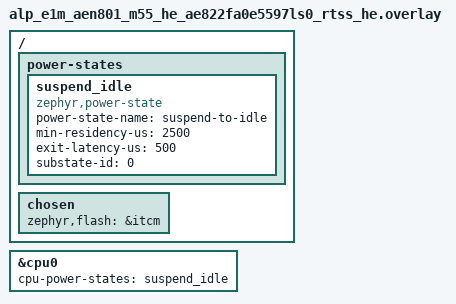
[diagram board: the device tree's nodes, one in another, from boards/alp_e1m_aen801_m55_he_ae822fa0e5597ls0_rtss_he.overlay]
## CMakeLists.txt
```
# SPDX-License-Identifier: Apache-2.0
#
# Stage-B PM deep-sleep (suspend-to-idle / IWIC) for the E1M-AEN801 (Alif
# Ensemble E8, Cortex-M55-HE).
#
# Brings a minimal Alif PM up over the pinned Zephyr 4.4.0 tree -- which ships no
# Alif pm_state_set and does not select HAS_PM -- and proves CONFIG_PM
# suspend-to-idle (deep IWIC sleep): the kernel idle path selects
# PM_STATE_SUSPEND_TO_IDLE, pm_state_set() (src/alif_pm_iwic.c) programs the AON
# WICCONTROL register (0x1A604010, bit8 WIC / bit9 IWIC) and parks the core in
# WFI; SysTick wakes it.  A wake beacon/heartbeat in global SRAM0 (0x02000000)
# advances each round.
#
# The HAS_PM select lives in this app's Kconfig; the suspend_idle power-state +
# cpu-power-states live in the board overlay.  No edit to upstream zephyr/.
#
# Standalone Zephyr app (no alp_project.py board.yaml flow): build with
#   ZEPHYR_BASE=<zephyr-base> west build \
#     -b alp_e1m_aen801_m55_he/ae822fa0e5597ls0/rtss_he <this-dir> -- \
#     "-DEXTRA_ZEPHYR_MODULES=<alp-sdk>;<hal_alif>"

cmake_minimum_required(VERSION 3.20)

# No DTC_OVERLAY_FILE: Zephyr applies boards/<fully-qualified-board>.overlay
# by itself, so the AEN801 and AEN803 targets each read their own file.

find_package(Zephyr REQUIRED HINTS $ENV{ZEPHYR_BASE})
project(aen_power_iwic LANGUAGES C)

target_sources(app PRIVATE
	src/main.c
	src/alif_pm_iwic.c
)
```

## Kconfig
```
# Copyright (c) 2026 Alp Lab AB
# SPDX-License-Identifier: Apache-2.0
#
# Stage-B PM bring-up over the pinned Zephyr 4.4.0 tree.
#
# `config PM` (subsys/pm/Kconfig) `depends on SYS_CLOCK_EXISTS && HAS_PM`, and
# `config HAS_PM` is a prompt-less bool that can ONLY be `select`ed by a SoC/board
# (it has no menuconfig prompt, so it cannot be set from prj.conf).  Pinned
# upstream Zephyr's Alif Ensemble SoC layer does NOT select it (only the
# alifsemi/zephyr_alif fork does).  This app-level Kconfig selects it so the
# CONFIG_PM=y in prj.conf becomes reachable -- the Tier-1.5 plumbing that, with
# src/alif_pm_iwic.c (pm_state_set) and the board overlay (suspend_idle
# power-state), brings a minimal Alif PM up with no edit to upstream zephyr/.
#
# Gated on the M55-HE SoC core (SOC_AE822FA0E5597LS0_RTSS_HE, true on any SKU
# built for that core): HAS_PM is only honoured (and pm_state_set is only
# correct) on the M55 core where this app's WICCONTROL(HE)=0x1A604010 hook
# applies -- a SoC-core fact, not a board/SKU one.

if SOC_AE822FA0E5597LS0_RTSS_HE

config HAS_PM
	default y

endif # SOC_AE822FA0E5597LS0_RTSS_HE

source "Kconfig.zephyr"
```

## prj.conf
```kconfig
# SPDX-License-Identifier: Apache-2.0
#
# Stage-B PM deep-sleep (suspend-to-idle / IWIC) for the E1M-AEN801 (Alif
# Ensemble E8, M55-HE), bench RAM-run via J-Link.  Unlike the peripheral
# examples (which now default to the Alp UART console), the PM apps deliberately
# keep the RAM console: console output must survive the deep-sleep/WFI path
# (a UART mid-suspend can gate its clock and drop bytes), so it is retargeted to
# a RAM buffer the human reads over SWD (mem8 of 'ram_console_buf') and decodes.

# --- RAM console (read 'ram_console_buf' over SWD) ---------------------------
CONFIG_RAM_CONSOLE=y
CONFIG_RAM_CONSOLE_BUFFER_SIZE=4096
CONFIG_UART_CONSOLE=n
CONFIG_CONSOLE=y
CONFIG_SERIAL=n
CONFIG_PRINTK=y

# --- Stage-B: bring up CONFIG_PM over the pinned tree ------------------------
# Pinned upstream Zephyr 4.4.0's Alif E8 SoC does NOT `select HAS_PM` and ships
# no pm_state_set (only the alifsemi/zephyr_alif fork's soc/alif/common/rtss/
# power.c does), so `config PM` (subsys/pm/Kconfig: depends on SYS_CLOCK_EXISTS
# && HAS_PM) was unreachable AND unlinkable.  This app closes BOTH halves at the
# app level with NO edit to upstream zephyr/:
#   - Kconfig (this app) `select HAS_PM`  -> makes `config PM` reachable;
#   - src/alif_pm_iwic.c defines pm_state_set()/pm_state_exit_post_ops() -> PM links;
#   - the board overlay enables the suspend_idle power-state + cpu-power-states.
CONFIG_PM=y

# Device PM is not needed for the CPU-only suspend-to-idle path and would pull in
# per-device suspend/resume the bench peripherals don't implement; keep it off.
CONFIG_PM_DEVICE=n

# SysTick is the M55 system clock (CONFIG_CORTEX_M_SYSTICK default y) and the
# wake source for the deep IWIC sleep.  SysTick is architectural exception #15,
# NOT an NVIC IRQ, so it is unaffected by the IWIC "interrupts 0-63 only" wake
# range -- it always wakes the WFI inside pm_state_set().  Tickless lets the
# kernel program SysTick to the next timeout before the PM idle, so the policy
# sees a real idle window and selects suspend-to-idle, and the wake k_timer
# still fires.
CONFIG_TICKLESS_KERNEL=y

# E8 D-cache maintenance loop hangs on this silicon (shared bench rule); and
# the SRAM0 liveness beacon (see src/main.c) must be coherent with the host
# read over the system bus, so keep the D-cache off (a cached beacon write
# could sit in the core's D-cache, unseen by the AXI-AP read).
CONFIG_DCACHE=n

# Keep the image small + deterministic for a RAM-run.  LOG MUST stay off --
# CONFIG_LOG=y reroutes printk into the logging subsystem, which has no
# RAM-console backend, so the RESULT line never reaches 'ram_console_buf'.
CONFIG_LOG=n
```

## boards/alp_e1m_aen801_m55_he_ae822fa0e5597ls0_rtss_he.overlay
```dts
/*
 * Copyright (c) 2026 Alp Lab AB
 * SPDX-License-Identifier: Apache-2.0
 *
 * Stage-B PM deep-sleep overlay for the E1M-AEN801 (Alif Ensemble E8, M55-HE),
 * bench RAM-run via J-Link.
 *
 * Two jobs:
 *
 *  1. The Tier-1.5 PM devicetree the pinned Zephyr 4.4.0 Alif HE dtsi omits.
 *     Pinned dts/arm/alif/ensemble/common/ensemble_rtss_he.dtsi has the cpu0
 *     node but NO `power-states` table and NO `cpu-power-states` (only the
 *     alifsemi/zephyr_alif fork's dtsi:153-197 has them).  We add the
 *     `suspend_idle` zephyr,power-state (transcribed from the fork dtsi:154-162:
 *     power-state-name "suspend-to-idle", min-residency-us 2500, exit-latency-us
 *     500, substate-id 0) and point cpu0 cpu-power-states at it, so the PM
 *     policy can select PM_STATE_SUSPEND_TO_IDLE and call the IWIC pm_state_set
 *     hook (src/alif_pm_iwic.c).  Only suspend_idle is enabled -- the deeper
 *     fork states (standby_s2ram / stop_s2ram / subsys_off) need the S2RAM
 *     context-save + Secure-Enclave path that is the full-fork-port follow-up,
 *     so they are deliberately not declared here.
 *
 *  2. The standard bench RAM-run retarget (run from ITCM, drop the MCUboot
 *     code-partition fixup), matching the sibling aen-* apps -- the smoke uses
 *     only architectural SysTick + a global-SRAM0 beacon (0x02000000), no
 *     peripheral nodes.
 */

/ {
	power-states {
		suspend_idle: suspend_idle {
			compatible = "zephyr,power-state";
			power-state-name = "suspend-to-idle";
			min-residency-us = <2500>;
			exit-latency-us = <500>;
			substate-id = <0>;
			status = "okay";
		};
	};

	chosen {
		/* PATH-REFERENCE form (&itcm), NOT the <&itcm> phandle-array form:
		 * the phandle-array form yields CONFIG_FLASH_SIZE=0 and the image
		 * overflows the (empty) FLASH region at link time. */
		zephyr,flash = &itcm;
		/delete-property/ zephyr,code-partition;
	};
};

/* Wire the M55-HE core to the suspend-to-idle power-state (the pinned cpu0 node
 * carries no cpu-power-states). */
&cpu0 {
	cpu-power-states = <&suspend_idle>;
};
```

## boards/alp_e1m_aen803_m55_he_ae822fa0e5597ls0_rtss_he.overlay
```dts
/*
 * Copyright (c) 2026 Alp Lab AB
 * SPDX-License-Identifier: Apache-2.0
 *
 * Stage-B PM deep-sleep overlay for the E1M-AEN803 (Alif Ensemble E8, M55-HE),
 * bench RAM-run via J-Link.
 *
 * Two jobs:
 *
 *  1. The Tier-1.5 PM devicetree the pinned Zephyr 4.4.0 Alif HE dtsi omits.
 *     Pinned dts/arm/alif/ensemble/common/ensemble_rtss_he.dtsi has the cpu0
 *     node but NO `power-states` table and NO `cpu-power-states` (only the
 *     alifsemi/zephyr_alif fork's dtsi:153-197 has them).  We add the
 *     `suspend_idle` zephyr,power-state (transcribed from the fork dtsi:154-162:
 *     power-state-name "suspend-to-idle", min-residency-us 2500, exit-latency-us
 *     500, substate-id 0) and point cpu0 cpu-power-states at it, so the PM
 *     policy can select PM_STATE_SUSPEND_TO_IDLE and call the IWIC pm_state_set
 *     hook (src/alif_pm_iwic.c).  Only suspend_idle is enabled -- the deeper
 *     fork states (standby_s2ram / stop_s2ram / subsys_off) need the S2RAM
 *     context-save + Secure-Enclave path that is the full-fork-port follow-up,
 *     so they are deliberately not declared here.
 *
 *  2. The standard bench RAM-run retarget (run from ITCM, drop the MCUboot
 *     code-partition fixup), matching the sibling aen-* apps -- the smoke uses
 *     only architectural SysTick + a global-SRAM0 beacon (0x02000000), no
 *     peripheral nodes.
 */

/ {
	power-states {
		suspend_idle: suspend_idle {
			compatible = "zephyr,power-state";
			power-state-name = "suspend-to-idle";
			min-residency-us = <2500>;
			exit-latency-us = <500>;
			substate-id = <0>;
			status = "okay";
		};
	};

	chosen {
		/* PATH-REFERENCE form (&itcm), NOT the <&itcm> phandle-array form:
		 * the phandle-array form yields CONFIG_FLASH_SIZE=0 and the image
		 * overflows the (empty) FLASH region at link time. */
		zephyr,flash = &itcm;
		/delete-property/ zephyr,code-partition;
	};
};

/* Wire the M55-HE core to the suspend-to-idle power-state (the pinned cpu0 node
 * carries no cpu-power-states). */
&cpu0 {
	cpu-power-states = <&suspend_idle>;
};
```

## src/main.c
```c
/*
 * Copyright (c) 2026 Alp Lab AB
 * SPDX-License-Identifier: Apache-2.0
 *
 * Stage-B low-power IWIC deep-sleep example for the E1M-AEN801 (Alif Ensemble
 * E8, Cortex-M55-HE).  Where Stage-A (aen-power-smoke) proved a plain
 * architectural WFI via the kernel idle path with NO PM subsystem, Stage-B
 * brings the Alif PM layer up over the pinned Zephyr 4.4.0 tree and proves the
 * CONFIG_PM suspend-to-idle (deep IWIC sleep) path:
 *
 *   1. boot, RAM console up;
 *   2. report the PM wiring as a bind-regcheck (CONFIG_PM built in, HAS_PM
 *      selected, the suspend_idle power-state node present + enabled, the
 *      pm_state_set IWIC hook linked);
 *   3. let the kernel idle into the PM policy: main blocks on a periodic
 *      k_timer's semaphore long enough that the PM policy selects
 *      PM_STATE_SUSPEND_TO_IDLE, so pm_state_set() programs WICCONTROL (deep
 *      IWIC sleep) and the core parks in WFI until SysTick wakes it;
 *   4. a wake "beacon" in global SRAM0 (0x02000000, master-agnostic addr)
 *      advances every round and k_uptime_get() moves forward -- i.e. we entered
 *      the PM deep-sleep state and came back, repeatedly;
 *   5. RESULT PASS / FAIL on one line.
 *
 * The beacon layout matches the Stage-A smoke (read mem32 of 0x02000000 over the
 * system AXI-AP as an AP-agnostic witness next to the console RESULT line):
 *   SRAM0[0] = 0xA11FE000  magic ("ALIVE")
 *   SRAM0[1] = SCB.CPUID         (0x411FD220 = Cortex-M55)
 *   SRAM0[2] = completed PM sleep/wake rounds (advances => core woke)
 *   SRAM0[3] = final RESULT code (1 = PASS, 2 = FAIL; 0 = not finished)
 *
 * WHY THIS IS THE STAGE-B MILESTONE
 * ---------------------------------
 * Pinned upstream Zephyr 4.4.0's Alif E8 SoC neither selects HAS_PM nor ships a
 * pm_state_set(), so CONFIG_PM was previously unreachable AND unlinkable (see
 * aen-power-smoke).  This example carries the Tier-1.5 plumbing that closes the
 * gap at the app/board level, with no edit to upstream zephyr/:
 *   - prj.conf turns CONFIG_PM on;
 *   - Kconfig (this app) `select HAS_PM` so `config PM` becomes reachable;
 *   - the board overlay enables the `suspend_idle` zephyr,power-state node and
 *     wires cpu0 cpu-power-states to it;
 *   - src/alif_pm_iwic.c supplies pm_state_set()/pm_state_exit_post_ops()
 *     driving the AON WICCONTROL register (0x1A604010, bit8 WIC / bit9 IWIC).
 *
 * suspend-to-idle (deep IWIC sleep) is the lightest Alif deep sleep: it needs no
 * S2RAM context save and no Secure-Enclave retention call, so it builds + runs
 * standalone.  suspend-to-ram / soft-off remain the full-fork-port follow-up.
 *
 * Console is the RAM buffer 'ram_console_buf' (see prj.conf); the bench app UART
 * is not USB-wired.  BENCH-VALIDATION app -- not a customer teaching example.
 */

#include <zephyr/kernel.h>
#include <zephyr/devicetree.h>
#include <zephyr/sys/printk.h>

/* Cortex-M System Control Block CPUID, by absolute address (no CMSIS header). */
/* Deep-sleep entries counted by src/alif_pm_iwic.c. */
extern volatile uint32_t aen_iwic_entries;

#define SCB_CPUID (*(volatile uint32_t *)0xE000ED00U)

/* Global SRAM0 liveness beacon (always-on on-chip SRAM, master-agnostic addr). */
#define SRAM0_BEACON ((volatile uint32_t *)0x02000000U)
#define BEACON_MAGIC 0xA11FE000U /* "ALIVE" */

#define RESULT_NONE 0U
#define RESULT_PASS 1U
#define RESULT_FAIL 2U

/* Number of PM sleep/wake rounds, and the wake-timer period.  The period is
 * comfortably above the suspend_idle min-residency-us (2500 us) so the PM policy
 * actually selects suspend-to-idle each idle window. */
#define PM_ROUNDS    8U
#define WAKE_TICK_MS 50U

/*
 * Compile-time PM-wiring facts -- the Stage-B bind-regcheck.  Each is a pure
 * Kconfig/DT predicate proving the PM plumbing is in place at build time; the
 * runtime rounds below then prove the state is actually entered + exited.
 */
#if defined(CONFIG_PM)
#define PM_BUILT 1
#else
#define PM_BUILT 0
#endif

#define SUSPEND_IDLE_NODE DT_NODELABEL(suspend_idle)
#define SUSPEND_IDLE_OK   DT_NODE_HAS_STATUS(SUSPEND_IDLE_NODE, okay)

static K_SEM_DEFINE(wake_sem, 0, 1);

static void wake_timer_fn(struct k_timer *t)
{
	ARG_UNUSED(t);
	k_sem_give(&wake_sem);
}

static K_TIMER_DEFINE(wake_timer, wake_timer_fn, NULL);

int main(void)
{
	uint32_t cpuid = SCB_CPUID;
	int64_t  t_start, t_now, t_prev;
	uint32_t advanced = 0U;

	SRAM0_BEACON[0] = BEACON_MAGIC;
	SRAM0_BEACON[1] = cpuid;
	SRAM0_BEACON[2] = 0U;
	SRAM0_BEACON[3] = RESULT_NONE;

	printk("\n=== AEN801 Stage-B PM deep-sleep (suspend-to-idle / IWIC) ===\n");

	/* Step 1: report the PM wiring (bind-regcheck of the Tier-1.5 plumbing). */
	printk("PM wiring: CONFIG_PM=%d suspend_idle-node=%d "
	       "WICCONTROL(HE)=0x1A604010 (bit8 WIC / bit9 IWIC)\n",
	       PM_BUILT,
	       (int)SUSPEND_IDLE_OK);

	if (!PM_BUILT || !SUSPEND_IDLE_OK) {
		SRAM0_BEACON[3] = RESULT_FAIL;
		printk("RESULT FAIL: PM not wired (CONFIG_PM=%d suspend_idle=%d) -- "
		       "Stage-B plumbing missing\n",
		       PM_BUILT,
		       (int)SUSPEND_IDLE_OK);
		return 0;
	}

	t_start = k_uptime_get();
	t_prev  = t_start;
	printk("boot uptime=%lld ms; CPUID=0x%08x; taking %u PM suspend-to-idle "
	       "rounds (~%u ms each)\n",
	       t_start,
	       cpuid,
	       PM_ROUNDS,
	       WAKE_TICK_MS);

	k_timer_start(&wake_timer, K_MSEC(WAKE_TICK_MS), K_MSEC(WAKE_TICK_MS));

	for (uint32_t i = 0U; i < PM_ROUNDS; i++) {
		/*
		 * Block on the timer semaphore: main de-schedules, the kernel
		 * idle thread runs the PM policy, which -- with the idle window
		 * (~WAKE_TICK_MS) above suspend_idle's min-residency-us --
		 * selects PM_STATE_SUSPEND_TO_IDLE.  pm_state_set() then programs
		 * WICCONTROL for deep IWIC sleep and parks the core in WFI; the
		 * SysTick-backed k_timer expiry wakes it and releases us.
		 */
		k_sem_take(&wake_sem, K_FOREVER);

		t_now = k_uptime_get();
		if (t_now > t_prev) {
			advanced++;
		}
		t_prev = t_now;

		SRAM0_BEACON[2] = i + 1U;

		printk("round %u/%u: woke from PM idle, beacon=%u uptime=%lld ms\n",
		       i + 1U,
		       PM_ROUNDS,
		       (uint32_t)SRAM0_BEACON[2],
		       t_now);
	}

	k_timer_stop(&wake_timer);
	t_now = k_uptime_get();

	if (SRAM0_BEACON[2] != PM_ROUNDS) {
		SRAM0_BEACON[3] = RESULT_FAIL;
		printk("RESULT FAIL: beacon=%u expected %u (a PM round did not "
		       "complete)\n",
		       (uint32_t)SRAM0_BEACON[2],
		       PM_ROUNDS);
		return 0;
	}
	if (aen_iwic_entries < PM_ROUNDS) {
		SRAM0_BEACON[3] = RESULT_FAIL;
		printk("RESULT FAIL: the IWIC hook ran %u times for %u rounds (the core "
		       "woke from plain idle, not from the PM deep-sleep state)\n",
		       (uint32_t)aen_iwic_entries,
		       PM_ROUNDS);
		return 0;
	}
	if (advanced != PM_ROUNDS) {
		SRAM0_BEACON[3] = RESULT_FAIL;
		printk("RESULT FAIL: uptime advanced on only %u/%u rounds "
		       "(core not waking from PM idle?)\n",
		       advanced,
		       PM_ROUNDS);
		return 0;
	}

	SRAM0_BEACON[3] = RESULT_PASS;
	printk("RESULT PASS: %u PM suspend-to-idle (deep IWIC) rounds entered + "
	       "woken; uptime %lld->%lld ms (beacon=%u, IWIC entries=%u)\n",
	       PM_ROUNDS,
	       t_start,
	       t_now,
	       (uint32_t)SRAM0_BEACON[2],
	       (uint32_t)aen_iwic_entries);
	return 0;
}
```

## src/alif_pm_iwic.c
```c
/*
 * Copyright (c) 2026 Alp Lab AB
 * SPDX-License-Identifier: Apache-2.0
 *
 * Stage-B Alif IWIC deep-sleep PM hook for the E1M-AEN801 (Ensemble E8,
 * Cortex-M55-HE) -- a minimal CONFIG_PM pm_state_set() that the pinned upstream
 * Zephyr 4.4.0 Alif SoC layer does NOT provide.
 *
 * WHY THIS FILE EXISTS (the pinned-tree PM gap)
 * ---------------------------------------------
 * Upstream Zephyr's PM subsystem calls pm_state_set() unconditionally
 * (subsys/pm/pm.c:246) and each SoC is expected to supply it (every other SoC
 * ships soc/<vendor>/.../power.c with a __weak pm_state_set).  The pinned
 * Zephyr 4.4.0 Alif Ensemble SoC layer ships NO power.c and does NOT
 * `select HAS_PM` (only the alifsemi/zephyr_alif FORK's
 * soc/alif/common/rtss/power.c does).  So over the pinned tree CONFIG_PM is
 * both unreachable (HAS_PM unselected) AND unlinkable (no pm_state_set).
 *
 * This Tier-1.5 file closes BOTH halves at the app/board level, with no edit to
 * upstream zephyr/:  the companion Kconfig `select HAS_PM`s, and this TU defines
 * pm_state_set()/pm_state_exit_post_ops() so CONFIG_PM links.  It is the in-tree
 * "thin over the vendor SDK" body the SoC layer omits; it deliberately
 * implements ONLY the suspend-to-idle (deep IWIC) state -- the lightest Alif
 * deep sleep, which needs no S2RAM context save and no Secure-Enclave call, so
 * it is buildable + bench-runnable standalone.  suspend-to-ram / soft-off
 * (EWIC + subsystem-off + SE retention config) are intentionally left to the
 * full fork power.c port; entering them here would be a no-op/!-EBUSY at best.
 *
 * REGISTER FACTS (all confirmed against the Alif CMSIS DFP, E8 = AE822FA0E5597)
 * ---------------------------------------------------------------------------
 *   AON base            = 0x1A604000   (DFP soc.h: AON_BASE)
 *   AON.RTSS_HE_CTRL    = AON + 0x10   (DFP soc.h AON_Type: RTSS_HE_CTRL @0x10)
 *   WICCONTROL (HE)     = 0x1A604010   (== AON.RTSS_HE_CTRL; this is the HE core
 *                                       WIC-control register)
 *   WICCONTROL bit 8    = WIC enable   (DFP pm.c WICCONTROL_WIC_Pos = 8)
 *   WICCONTROL bit 9    = IWIC select  (DFP pm.c WICCONTROL_IWIC_Pos = 9;
 *                                       1 = IWIC, 0 = EWIC)
 * The deep-sleep entry sequence (set WICCONTROL WIC|IWIC, raise CPDLPSTATE.CLPSTATE
 * to ON_CLK_OFF to avoid core state loss, set SCB SLEEPDEEP, DSB/ISB, WFI, then
 * restore) mirrors the Alif DFP pm.c pm_core_enter_deep_sleep() and the
 * Apache-2.0 fork soc/alif/common/rtss/power.c.  IWIC wake sources are NVIC
 * interrupts 0-63 + events/NMI/debug (DFP pm.c note); the M55 SysTick is
 * architectural exception #15, NOT an NVIC IRQ, and always wakes WFI/WFE.
 *
 * Console / bench: this file carries no I/O; the example main() reports the
 * RESULT line over the RAM console.  No /home paths, no DFP source, no
 * license-gated content -- only the transcribed register addresses/bits above.
 */

#include <zephyr/kernel.h>
#include <zephyr/pm/pm.h>
#include <zephyr/sys/sys_io.h>

/*
 * WICCONTROL for the RTSS-HE core, by absolute address (the pinned Alif SoC
 * header exposes no AON struct / macro -- soc.h is bare CMSIS).  HE core only:
 * the HP core would use AON.RTSS_HP_CTRL = AON_BASE + 0x0 = 0x1A604000.
 */
#define AEN_AON_BASE      0x1A604000UL
#define AEN_WICCONTROL_HE (AEN_AON_BASE + 0x10UL) /* AON.RTSS_HE_CTRL */

#define WICCONTROL_WIC_Pos  8U
#define WICCONTROL_WIC_Msk  (1UL << WICCONTROL_WIC_Pos)
#define WICCONTROL_IWIC_Pos 9U
#define WICCONTROL_IWIC_Msk (1UL << WICCONTROL_IWIC_Pos)

/* WICCONTROL bit9 select values. */
#define PM_WIC_IS_EWIC 0U /* WIC used is EWIC */
#define PM_WIC_IS_IWIC 1U /* WIC used is IWIC */

/*
 * CPDLPSTATE.CLPSTATE low-power-state field values (M55 core power domain).
 * We raise to ON_CLK_OFF before an IWIC sleep so the core does NOT lose state
 * (the IWIC + CPU share a power domain, so both must stay on to wake).
 */
#define PM_LPSTATE_ON         0U
#define PM_LPSTATE_ON_CLK_OFF 1U

/*
 * Architectural deep WIC sleep: program WICCONTROL, set SLEEPDEEP, barrier, WFI.
 * Called with interrupts disabled.  Returns after the wake interrupt fires.
 */
/* Deep-sleep entries actually taken by the PM hook. main.c requires one per
 * round: a wake alone would also follow a plain kernel-idle WFI, so it proves
 * nothing about the PM policy having selected this state. */
volatile uint32_t aen_iwic_entries;

static void aen_enter_wic_sleep(uint32_t wic_is_iwic)
{
	uint32_t regval = WICCONTROL_WIC_Msk | (wic_is_iwic ? WICCONTROL_IWIC_Msk : 0U);

	aen_iwic_entries++;

	/* Select deep WIC sleep of the requested type (IWIC here). */
	sys_write32(regval, AEN_WICCONTROL_HE);

	/* Request deep sleep at the architectural level. */
	SCB->SCR |= SCB_SCR_SLEEPDEEP_Msk;
	__DSB();
	__ISB();

	/* Park the core.  An IWIC wake source (NVIC IRQ 0-63 / event / SysTick
	 * exception) brings it back here. */
	__WFI();

	/* Leave deep sleep and clear the WIC selection. */
	SCB->SCR &= ~SCB_SCR_SLEEPDEEP_Msk;
	sys_write32(0U, AEN_WICCONTROL_HE);
	__DSB();
	__ISB();
}

/*
 * suspend-to-idle == Alif "deep IWIC sleep": raise CLPSTATE to ON_CLK_OFF so the
 * core keeps its state, take the IWIC WIC sleep, then restore CLPSTATE.
 */
static void aen_enter_deep_sleep_iwic(void)
{
	uint32_t old_cpdlpstate = PWRMODCTL->CPDLPSTATE;

	PWRMODCTL->CPDLPSTATE = (old_cpdlpstate & ~PWRMODCTL_CPDLPSTATE_CLPSTATE_Msk) |
	                        (PM_LPSTATE_ON_CLK_OFF << PWRMODCTL_CPDLPSTATE_CLPSTATE_Pos);

	aen_enter_wic_sleep(PM_WIC_IS_IWIC);

	PWRMODCTL->CPDLPSTATE = old_cpdlpstate;
}

/*
 * PM subsystem entry: lower the CPU into the requested state.  Only
 * suspend-to-idle (deep IWIC sleep) is implemented on this batch; the deeper
 * Alif states are documented as the full-fork-port work item.  Called by the PM
 * idle path with the scheduler locked.
 */
void pm_state_set(enum pm_state state, uint8_t substate_id)
{
	ARG_UNUSED(substate_id);

	switch (state) {
	case PM_STATE_SUSPEND_TO_IDLE:
		__disable_irq();
		__set_BASEPRI(0);
		aen_enter_deep_sleep_iwic();
		break;
	default:
		/* Deeper states not wired in this Stage-B body -- the PM policy
		 * only ever selects suspend-to-idle here (it is the sole
		 * enabled power-state in devicetree). */
		break;
	}
}

/*
 * PM subsystem exit: re-enable interrupts the idle path masked before sleeping.
 * Mirrors the fork pm_state_exit_post_ops().
 */
void pm_state_exit_post_ops(enum pm_state state, uint8_t substate_id)
{
	ARG_UNUSED(state);
	ARG_UNUSED(substate_id);

	__enable_irq();

	/* Re-enable interrupts disabled when the kernel entered idle. */
	irq_unlock(0);
}
```
